# STM32F7x6 register map
File version: 1.6
CPU: CM7 r0p1, little endian, MPU, FPU, 4 interrupt priority bits
Registers are 32-bit, read-write, reset 0x0 unless marked. A register's access mark holds for its fields unless they carry their own. Offsets are from the block's base; [hi:lo] are bit positions; 'fields as' and 'values as' point back to an identical list.

## ADC_Common — Common ADC registers
Base 0x40012300
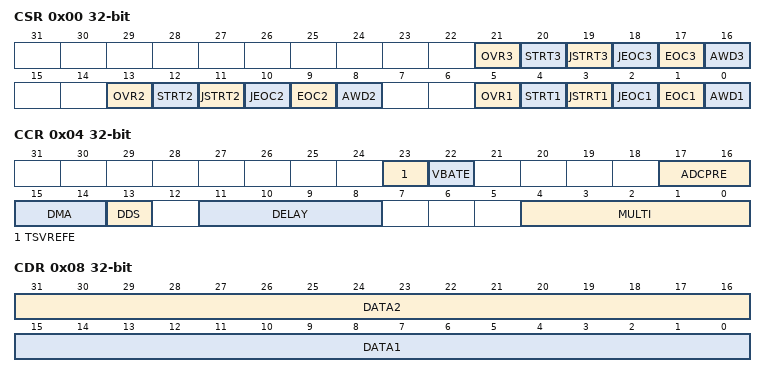
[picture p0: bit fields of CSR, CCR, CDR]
0x00 CSR ro — ADC Common status register
  [21] OVR3 — Overrun flag of ADC3
    on read: 0=No overrun occurred; 1=Overrun occurred
  [20] STRT3 — Regular channel Start flag of ADC 3
    on read: 0=NotStarted (No regular channel conversion started); 1=Started (Regular channel conversion has started)
  [19] JSTRT3 — Injected channel Start flag of ADC 3
    on read: 0=NotStarted (No injected channel conversion started); 1=Started (Injected channel conversion has started)
  [18] JEOC3 — Injected channel end of conversion of ADC 3
    on read: 0=NotComplete (Conversion is not complete); 1=Complete (Conversion complete)
  [17] EOC3 — End of conversion of ADC 3
    values as JEOC3
  [16] AWD3 — Analog watchdog flag of ADC 3
    on read: 0=NoEvent (No analog watchdog event occurred); 1=Event (Analog watchdog event occurred)
  [13] OVR2 — Overrun flag of ADC 2
    on read: 0=No overrun occurred; 1=Overrun occurred
  [12] STRT2 — Regular channel Start flag of ADC 2
    values as STRT3
  [11] JSTRT2 — Injected channel Start flag of ADC 2
    values as JSTRT3
  [10] JEOC2 — Injected channel end of conversion of ADC 2
    values as JEOC3
  [9] EOC2 — End of conversion of ADC 2
    values as JEOC3
  [8] AWD2 — Analog watchdog flag of ADC 2
    values as AWD3
  [5] OVR1 — Overrun flag of ADC 1
    on read: 0=No overrun occurred; 1=Overrun occurred
  [4] STRT1 — Regular channel Start flag of ADC 1
    values as STRT3
  [3] JSTRT1 — Injected channel Start flag of ADC 1
    values as JSTRT3
  [2] JEOC1 — Injected channel end of conversion of ADC 1
    values as JEOC3
  [1] EOC1 — End of conversion of ADC 1
    values as JEOC3
  [0] AWD1 — Analog watchdog flag of ADC 1
    values as AWD3
0x04 CCR — ADC common control register
  [23] TSVREFE — Temperature sensor and VREFINT enable
    0=Disabled (Temperature sensor and V_REFINT channel disabled); 1=Enabled (Temperature sensor and V_REFINT channel enabled)
  [22] VBATE — VBAT enable
    0=Disabled (V_BAT channel disabled); 1=Enabled (V_BAT channel enabled)
  [17:16] ADCPRE — ADC prescaler
    0=Div2 (PCLK2 divided by 2); 1=Div4 (PCLK2 divided by 4); 2=Div6 (PCLK2 divided by 6); 3=Div8 (PCLK2 divided by 8)
  [15:14] DMA — Direct memory access mode for multi ADC mode
    0=Disabled (DMA mode disabled); 1=Mode1 (DMA mode 1 enabled (2 / 3 half-words one by one - 1 then 2 then 3)); 2=Mode2 (DMA mode 2 enabled (2 / 3 half-words by pairs - 2&1 then 1&3 then 3&2)); 3=Mode3 (DMA mode 3 enabled (2 / 3 half-words by pairs - 2&1 then 1&3 then 3&2))
  [13] DDS — DMA disable selection for multi-ADC mode
    0=Single (No new DMA request is issued after the last transfer); 1=Continuous (DMA requests are issued as long as data are converted and DMA=01, 10 or 11)
  [11:8] DELAY — Delay between 2 sampling phases
  [4:0] MULTI — Multi ADC mode selection
    0=Independent (All the ADCs independent: independent mode); 1=DualRJ (Dual ADC1 and ADC2, combined regular and injected simultaneous mode); 2=DualRA (Dual ADC1 and ADC2, combined regular and alternate trigger mode); 5=DualJ (Dual ADC1 and ADC2, injected simultaneous mode only); 6=DualR (Dual ADC1 and ADC2, regular simultaneous mode only); 7=DualI (Dual ADC1 and ADC2, interleaved mode only); 9=Dual ADC1 and ADC2, alternate trigger mode only; 17=TripleRJ (Triple ADC, regular and injected simultaneous mode); 18=TripleRA (Triple ADC, regular and alternate trigger mode); 21=TripleJ (Triple ADC, injected simultaneous mode only); 22=TripleR (Triple ADC, regular simultaneous mode only); 23=TripleI (Triple ADC, interleaved mode only); 24=Triple ADC, alternate trigger mode only
0x08 CDR ro — ADC common regular data register for dual and triple modes
  [31:16] DATA2 — 2nd data item of a pair of regular conversions
  [15:0] DATA1 — 1st data item of a pair of regular conversions
